# mb9bf566k register map
Vendor: Cypress; Series: mb9bf560l; File version: 1.2
CPU: CM4 r0p1, little endian, MPU, FPU, 4 interrupt priority bits
Registers are 8-bit, read-write, reset 0x0 unless marked. A register's access mark holds for its fields unless they carry their own. Offsets are from the block's base; [hi:lo] are bit positions.

## WORKFLASH_IF — WorkFlash Memory
Base 0x200E0000
0x00 WFASZR 32-bit reset 0x1 — WorkFlash Access Size Register
  [0] ASZ — WorkFlash Access Size
0x04 WFRWTR 32-bit reset 0x4 — WorkFlash Read Wait Register
  [2:0] RWT — Read Wait Cycle
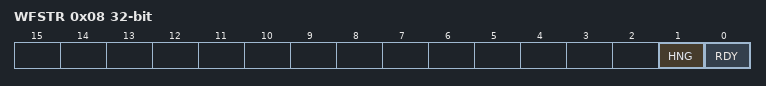
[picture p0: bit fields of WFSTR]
0x08 WFSTR 32-bit ro — WorkFlash Status Register
  [1] HNG — WorkFlash Hang
  [0] RDY — WorkFlash Rdy

## FLASH_IF — Flash Memory
Base 0x40000000
0x00 FASZR 32-bit reset 0x2 — Flash Access Size Register
  [1:0] ASZ — Access Size
0x04 FRWTR 32-bit reset 0x2 — Flash Read Wait Register
  [1:0] RWT — Read Wait Cycle
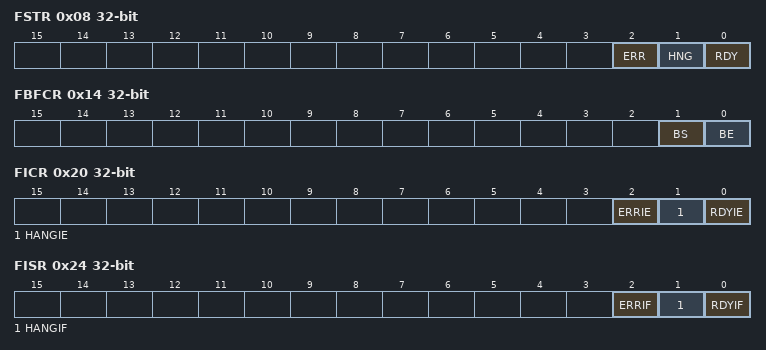
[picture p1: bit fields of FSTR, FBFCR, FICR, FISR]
0x08 FSTR 32-bit ro — Flash Status Register
  [2] ERR rw — Flash ECC Error
  [1] HNG — Flash Hang flag
  [0] RDY — Flash Rdy
0x10 FSYNDN 32-bit — Flash Sync Down Register
  [2:0] SD — Sync Down
0x14 FBFCR 32-bit — Flash Buffer Control Register
  [1] BS ro — Buffer Status
  [0] BE — Buffer Enable
0x20 FICR 32-bit — Flash Interrupt Control Register
  [2] ERRIE — Flash ECC Error Interrupt Enable
  [1] HANGIE — HANG Interrupt Enable
  [0] RDYIE — RDY Interrupt Enable
0x24 FISR 32-bit — Flash Interrupt Status Register
  [2] ERRIF ro — Flash ECC Error Interrupt Flag
  [1] HANGIF ro — HANG Interrupt Flag
  [0] RDYIF ro — RDY Interrupt Flag
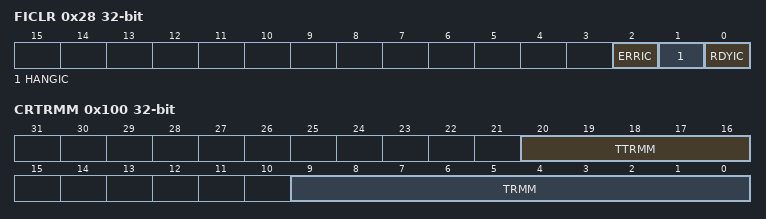
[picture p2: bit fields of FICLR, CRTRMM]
0x28 FICLR 32-bit wo — Flash Interrupt Clear Register
  [2] ERRIC rw — Flash ECC Error Interrupt Clear
  [1] HANGIC rw — HANG Interrupt Clear
  [0] RDYIC rw — RDY Interrupt Clear
0x100 CRTRMM 32-bit ro reset not defined — CR Trimming Data Mirror Register
  [20:16] TTRMM — CR Temperature Trimming Data Mirror
  [9:0] TRMM — CR Trimming Data Mirror

## UNIQUE_ID
Base 0x40000200
0x00 UIDR0 32-bit ro — Unique ID Register 0
  [31:4] UID — Unique ID 27 through 0
0x04 UIDR1 32-bit ro — Unique ID Register 1
  [12:0] UID — Unique ID 40 through 28

## ECC_CAPTURE — ECC Capture Address
Base 0x40000300
0x00 FERRAD 32-bit ro — Flash ECC Error Address Capture Register
  [22:0] ERRAD — Flash ECC Error Address Capture

## CRTRIM — CR Trimming Registers
Base 0x4002E000
0x00 MCR_PSR reset 0x1 — High-speed CR oscillation Frequency Division Setup Register
  [2:0] CSR — High-speed CR oscillation frequency division ratio setting bits
0x04 MCR_FTRM 16-bit reset 0x1EF — High-speed CR oscillation Frequency Trimming Register
  [9:0] TRD — Frequency trimming setup bits
0x08 MCR_TTRM reset 0x10 — High-speed CR oscillation Temperature Trimming Register
  [4:0] TRT — Temperature trimming setup bits
0x0C MCR_RLR 32-bit reset 0x1 — High-Speed CR Oscillation Register Write-Protect Register
  [31:0] TRMLCK — Register write-protect bits

## SWWDT — Software Watchdog Timer
Base 0x40012000
0x00 WDOGLOAD 32-bit reset 0xFFFFFFFF — Software Watchdog Timer Load Register
0x04 WDOGVALUE 32-bit ro reset 0xFFFFFFFF — Software Watchdog Timer Value Register
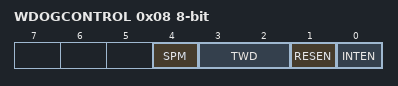
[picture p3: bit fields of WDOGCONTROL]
0x08 WDOGCONTROL — Software Watchdog Timer Control Register
  [4] SPM — Software Watchdog window watchdog mode enable bit
  [3:2] TWD — Timing window setting bit of the software watchdog
  [1] RESEN — Reset enable bit of the software watchdog
  [0] INTEN — Interrupt and counter enable bit of the software watchdog
0x0C WDOGINTCLR 32-bit reset 0xFFFFFFFF — Software Watchdog Timer Clear Register
0x10 WDOGRIS ro — Software Watchdog Timer Interrupt Status Register
  [0] RIS — Software watchdog interrupt status bit
0x18 WDOGSPMC — Software Watchdog Timer Window Watchdog Mode Control Register
  [0] TGR ro — Software watchdog trigger type bit
0xC00 WDOGLOCK 32-bit — Software Watchdog Timer Lock Register

## HWWDT — Hardware Watchdog Timer
Base 0x40011000
0x00 WDG_LDR 32-bit reset 0xFFFF — Hardware Watchdog Timer Load Register
0x04 WDG_VLR 32-bit ro — Hardware Watchdog Timer Value Register
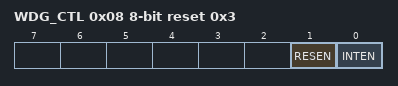
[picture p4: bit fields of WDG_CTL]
0x08 WDG_CTL reset 0x3 — Hardware Watchdog Timer Control Register
  [1] RESEN — Hardware watchdog reset enable bit
  [0] INTEN — Hardware watchdog interrupt and counter enable bit
0x0C WDG_ICL reset 0xFF (reset mask 0x0) — Hardware Watchdog Timer Clear Register
0x10 WDG_RIS ro reset 0xFF (reset mask 0x0) — Hardware Watchdog Timer Interrupt Status Register
  [0] RIS — Hardware watchdog interrupt status bit
0xC00 WDG_LCK 32-bit reset 0x1 — Hardware Watchdog Timer Lock Register

## Notices in the file
Copyright (C) 2013 Spansion LLC. All Rights Reserved.
This software is owned and published by:
Spansion LLC, 915 DeGuigne Dr. Sunnyvale, CA  94088-3453 ("Spansion").
BY DOWNLOADING, INSTALLING OR USING THIS SOFTWARE, YOU AGREE TO BE BOUND
BY ALL THE TERMS AND CONDITIONS OF THIS AGREEMENT.
This software contains source code for use with Spansion
components. This software is licensed by Spansion to be adapted only
for use in systems utilizing Spansion components. Spansion shall not be
responsible for misuse or illegal use of this software for devices not
supported herein.  Spansion is providing this software "AS IS" and will
not be responsible for issues arising from incorrect user implementation
of the software.
SPANSION MAKES NO WARRANTY, EXPRESS OR IMPLIED, ARISING BY LAW OR OTHERWISE,
REGARDING THE SOFTWARE (INCLUDING ANY ACOOMPANYING WRITTEN MATERIALS),
ITS PERFORMANCE OR SUITABILITY FOR YOUR INTENDED USE, INCLUDING,
WITHOUT LIMITATION, THE IMPLIED WARRANTY OF MERCHANTABILITY, THE IMPLIED
WARRANTY OF FITNESS FOR A PARTICULAR PURPOSE OR USE, AND THE IMPLIED
WARRANTY OF NONINFRINGEMENT.
SPANSION SHALL HAVE NO LIABILITY (WHETHER IN CONTRACT, WARRANTY, TORT,
NEGLIGENCE OR OTHERWISE) FOR ANY DAMAGES WHATSOEVER (INCLUDING, WITHOUT
LIMITATION, DAMAGES FOR LOSS OF BUSINESS PROFITS, BUSINESS INTERRUPTION,
LOSS OF BUSINESS INFORMATION, OR OTHER PECUNIARY LOSS) ARISING FROM USE OR
INABILITY TO USE THE SOFTWARE, INCLUDING, WITHOUT LIMITATION, ANY DIRECT,
INDIRECT, INCIDENTAL, SPECIAL OR CONSEQUENTIAL DAMAGES OR LOSS OF DATA,
SAVINGS OR PROFITS,
EVEN IF SPANSION HAS BEEN ADVISED OF THE POSSIBILITY OF SUCH DAMAGES.
YOU ASSUME ALL RESPONSIBILITIES FOR SELECTION OF THE SOFTWARE TO ACHIEVE YOUR
INTENDED RESULTS, AND FOR THE INSTALLATION OF, USE OF, AND RESULTS OBTAINED
FROM, THE SOFTWARE.
This software may be replicated in part or whole for the licensed use,
with the restriction that this Disclaimer and Copyright notice must be
included with each copy of this software, whether used in part or whole,
at all times.
